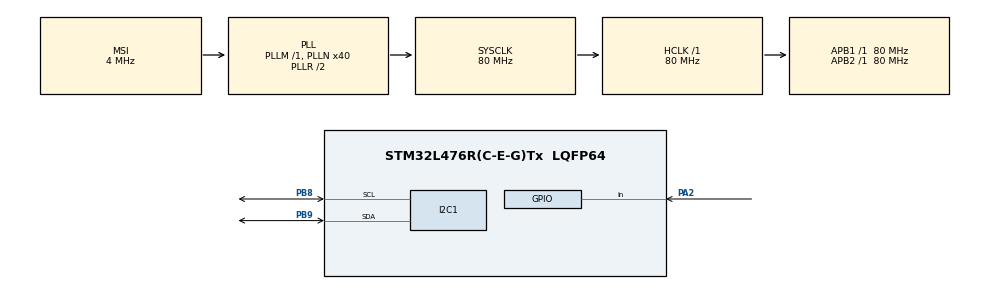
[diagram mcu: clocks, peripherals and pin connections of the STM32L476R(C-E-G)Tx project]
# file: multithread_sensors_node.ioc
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FREERTOS.Mutexes01=I2C1_bus,Dynamic,NULL,Available
FREERTOS.Queues01=i2c_gyro,8,DebugMsg_t,0,Dynamic,NULL,NULL
FREERTOS.Tasks01=health_debug_ta,24,128,check_cpu_health,Default,NULL,Dynamic,NULL,NULL;i2c_read_write_,24,256,i2c_read_write,Default,NULL,Dynamic,NULL,NULL;DHT11_TH_Sensor,25,256,dht11_rw,Default,NULL,Dynamic,NULL,NULL
FREERTOS.configTOTAL_HEAP_SIZE=5000
I2C1.Timing=0x10D19CE4
Mcu.Family=STM32L4
Mcu.Name=STM32L476R(C-E-G)Tx
Mcu.Package=LQFP64
NVIC.PriorityGroup=NVIC_PRIORITYGROUP_4
NVIC.TIM6_DAC_IRQn=true\:15\:0\:false\:false\:true\:false\:false\:true\:true
NVIC.TimeBase=TIM6_DAC_IRQn
NVIC.TimeBaseIP=TIM6
PA13\ (JTMS-SWDIO).Mode=Serial_Wire
PA13\ (JTMS-SWDIO).Signal=SYS_JTMS-SWDIO
PA14\ (JTCK-SWCLK).Mode=Serial_Wire
PA14\ (JTCK-SWCLK).Signal=SYS_JTCK-SWCLK
PA2.Signal=GPIO_Input
PB8.Mode=I2C
PB8.Signal=I2C1_SCL
PB9.Mode=I2C
PB9.Signal=I2C1_SDA
ProjectManager.HeapSize=0x200
ProjectManager.StackSize=0x400
ProjectManager.TargetToolchain=STM32CubeIDE
RCC.AHBFreq_Value=80000000
RCC.APB1Freq_Value=80000000
RCC.APB1TimFreq_Value=80000000
RCC.APB2Freq_Value=80000000
RCC.APB2TimFreq_Value=80000000
RCC.CortexFreq_Value=80000000
RCC.HCLKFreq_Value=80000000
RCC.HSE_VALUE=8000000
RCC.HSI_VALUE=16000000
RCC.LSE_VALUE=32768
RCC.MSI_VALUE=4000000
RCC.PLLN=40
RCC.SYSCLKFreq_VALUE=80000000
RCC.SYSCLKSource=RCC_SYSCLKSOURCE_PLLCLK
RCC.VCOOutputFreq_Value=160000000
TIM2.AutoReloadPreload=TIM_AUTORELOAD_PRELOAD_ENABLE
TIM2.Period=65535-1
TIM2.Prescaler=80-1
TIM2.TIM_MasterOutputTrigger=TIM_TRGO_RESET
TIM2.TIM_MasterSlaveMode=TIM_MASTERSLAVEMODE_DISABLE
VP_FREERTOS_VS_CMSIS_V2.Mode=CMSIS_V2
VP_SYS_VS_tim6.Mode=TIM6
VP_TIM2_VS_ClockSourceINT.Mode=Internal
board=custom

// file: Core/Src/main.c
/* USER CODE BEGIN Header */
/**
  ******************************************************************************
  * @file           : main.c
  * @brief          : Main program body
  ******************************************************************************
  * @attention
  *
  * Copyright (c) 2026 STMicroelectronics.
  * All rights reserved.
  *
  * This software is licensed under terms that can be found in the LICENSE file
  * in the root directory of this software component.
  * If no LICENSE file comes with this software, it is provided AS-IS.
  *
  ******************************************************************************
  */
/* USER CODE END Header */
#include "main.h"
#include "cmsis_os.h"

I2C_HandleTypeDef hi2c1;

TIM_HandleTypeDef htim2;

/* Definitions for health_debug_ta */
osThreadId_t health_debug_taHandle;
const osThreadAttr_t health_debug_ta_attributes = {
  .name = "health_debug_ta",
  .stack_size = 128 * 4,
  .priority = (osPriority_t) osPriorityNormal,
};
/* Definitions for i2c_read_write_ */
osThreadId_t i2c_read_write_Handle;
const osThreadAttr_t i2c_read_write__attributes = {
  .name = "i2c_read_write_",
  .stack_size = 256 * 4,
  .priority = (osPriority_t) osPriorityNormal,
};
/* Definitions for DHT11_TH_Sensor */
osThreadId_t DHT11_TH_SensorHandle;
const osThreadAttr_t DHT11_TH_Sensor_attributes = {
  .name = "DHT11_TH_Sensor",
  .stack_size = 256 * 4,
  .priority = (osPriority_t) osPriorityNormal1,
};
/* Definitions for i2c_gyro */
osMessageQueueId_t i2c_gyroHandle;
const osMessageQueueAttr_t i2c_gyro_attributes = {
  .name = "i2c_gyro"
};
/* Definitions for I2C1_bus */
osMutexId_t I2C1_busHandle;
const osMutexAttr_t I2C1_bus_attributes = {
  .name = "I2C1_bus"
};

void SystemClock_Config(void);
static void MX_GPIO_Init(void);
static void MX_I2C1_Init(void);
static void MX_TIM2_Init(void);
void check_cpu_health(void *argument);
void i2c_read_write(void *argument);
void dht11_rw(void *argument);

/* USER CODE BEGIN PFP */
dht11_t dht;
/* USER CODE END PFP */

int main(void)
{

  /* USER CODE BEGIN 1 */
	char buff[15];
  /* USER CODE END 1 */

  /* MCU Configuration--------------------------------------------------------*/

  /* Reset of all peripherals, Initializes the Flash interface and the Systick. */
  HAL_Init();

  /* Configure the system clock */
  SystemClock_Config();

  /* Initialize all configured peripherals */
  MX_GPIO_Init();
  MX_I2C1_Init();
  MX_TIM2_Init();
  /* USER CODE BEGIN 2 */

  init_dht11(&dht, &htim2, GPIOA, GPIO_PIN_8);

  HAL_Delay(100);
  /* USER CODE END 2 */

  /* Init scheduler */
  osKernelInitialize();
  /* Create the mutex(es) */
  /* creation of I2C1_bus */
  I2C1_busHandle = osMutexNew(&I2C1_bus_attributes);

  /* Create the queue(s) */
  /* creation of i2c_gyro */
  i2c_gyroHandle = osMessageQueueNew (8, sizeof(DebugMsg_t), &i2c_gyro_attributes);

  /* USER CODE BEGIN RTOS_QUEUES */
  if(i2c_gyroHandle == NULL)
  {
	  sprintf(buff, "Queue Error");
	  send_string(buff);
  }
  /* add queues, ... */
  /* USER CODE END RTOS_QUEUES */

  /* Create the thread(s) */
  /* creation of health_debug_ta */
  health_debug_taHandle = osThreadNew(check_cpu_health, NULL, &health_debug_ta_attributes);

  /* creation of i2c_read_write_ */
//  i2c_read_write_Handle = osThreadNew(i2c_read_write, NULL, &i2c_read_write__attributes);

  /* creation of DHT11_TH_Sensor */
  DHT11_TH_SensorHandle = osThreadNew(dht11_rw, NULL, &DHT11_TH_Sensor_attributes);

  /* Start scheduler */
  osKernelStart();

  /* We should never get here as control is now taken by the scheduler */

  /* Infinite loop */
  while (1)
  {

  }
}

void SystemClock_Config(void)
{
  RCC_OscInitTypeDef RCC_OscInitStruct = {0};
  RCC_ClkInitTypeDef RCC_ClkInitStruct = {0};

  /** Configure the main internal regulator output voltage
  */
  if (HAL_PWREx_ControlVoltageScaling(PWR_REGULATOR_VOLTAGE_SCALE1) != HAL_OK)
  {
    Error_Handler();
  }

  /** Initializes the RCC Oscillators according to the specified parameters
  * in the RCC_OscInitTypeDef structure.
  */
  RCC_OscInitStruct.OscillatorType = RCC_OSCILLATORTYPE_MSI;
  RCC_OscInitStruct.MSIState = RCC_MSI_ON;
  RCC_OscInitStruct.MSICalibrationValue = 0;
  RCC_OscInitStruct.MSIClockRange = RCC_MSIRANGE_6;
  RCC_OscInitStruct.PLL.PLLState = RCC_PLL_ON;
  RCC_OscInitStruct.PLL.PLLSource = RCC_PLLSOURCE_MSI;
  RCC_OscInitStruct.PLL.PLLM = 1;
  RCC_OscInitStruct.PLL.PLLN = 40;
  RCC_OscInitStruct.PLL.PLLP = RCC_PLLP_DIV7;
  RCC_OscInitStruct.PLL.PLLQ = RCC_PLLQ_DIV2;
  RCC_OscInitStruct.PLL.PLLR = RCC_PLLR_DIV2;
  if (HAL_RCC_OscConfig(&RCC_OscInitStruct) != HAL_OK)
  {
    Error_Handler();
  }

  /** Initializes the CPU, AHB and APB buses clocks
  */
  RCC_ClkInitStruct.ClockType = RCC_CLOCKTYPE_HCLK|RCC_CLOCKTYPE_SYSCLK
                              |RCC_CLOCKTYPE_PCLK1|RCC_CLOCKTYPE_PCLK2;
  RCC_ClkInitStruct.SYSCLKSource = RCC_SYSCLKSOURCE_PLLCLK;
  RCC_ClkInitStruct.AHBCLKDivider = RCC_SYSCLK_DIV1;
  RCC_ClkInitStruct.APB1CLKDivider = RCC_HCLK_DIV1;
  RCC_ClkInitStruct.APB2CLKDivider = RCC_HCLK_DIV1;

  if (HAL_RCC_ClockConfig(&RCC_ClkInitStruct, FLASH_LATENCY_4) != HAL_OK)
  {
    Error_Handler();
  }
}

static void MX_I2C1_Init(void)
{

  hi2c1.Instance = I2C1;
  hi2c1.Init.Timing = 0x10D19CE4;
  hi2c1.Init.OwnAddress1 = 0;
  hi2c1.Init.AddressingMode = I2C_ADDRESSINGMODE_7BIT;
  hi2c1.Init.DualAddressMode = I2C_DUALADDRESS_DISABLE;
  hi2c1.Init.OwnAddress2 = 0;
  hi2c1.Init.OwnAddress2Masks = I2C_OA2_NOMASK;
  hi2c1.Init.GeneralCallMode = I2C_GENERALCALL_DISABLE;
  hi2c1.Init.NoStretchMode = I2C_NOSTRETCH_DISABLE;
  if (HAL_I2C_Init(&hi2c1) != HAL_OK)
  {
    Error_Handler();
  }

  /** Configure Analogue filter
  */
  if (HAL_I2CEx_ConfigAnalogFilter(&hi2c1, I2C_ANALOGFILTER_ENABLE) != HAL_OK)
  {
    Error_Handler();
  }

  /** Configure Digital filter
  */
  if (HAL_I2CEx_ConfigDigitalFilter(&hi2c1, 0) != HAL_OK)
  {
    Error_Handler();
  }

}

static void MX_TIM2_Init(void)
{

  TIM_ClockConfigTypeDef sClockSourceConfig = {0};
  TIM_MasterConfigTypeDef sMasterConfig = {0};

  htim2.Instance = TIM2;
  htim2.Init.Prescaler = 80-1;
  htim2.Init.CounterMode = TIM_COUNTERMODE_UP;
  htim2.Init.Period = 65535-1;
  htim2.Init.ClockDivision = TIM_CLOCKDIVISION_DIV1;
  htim2.Init.AutoReloadPreload = TIM_AUTORELOAD_PRELOAD_ENABLE;
  if (HAL_TIM_Base_Init(&htim2) != HAL_OK)
  {
    Error_Handler();
  }
  sClockSourceConfig.ClockSource = TIM_CLOCKSOURCE_INTERNAL;
  if (HAL_TIM_ConfigClockSource(&htim2, &sClockSourceConfig) != HAL_OK)
  {
    Error_Handler();
  }
  sMasterConfig.MasterOutputTrigger = TIM_TRGO_RESET;
  sMasterConfig.MasterSlaveMode = TIM_MASTERSLAVEMODE_DISABLE;
  if (HAL_TIMEx_MasterConfigSynchronization(&htim2, &sMasterConfig) != HAL_OK)
  {
    Error_Handler();
  }

}

static void MX_GPIO_Init(void)
{
  GPIO_InitTypeDef GPIO_InitStruct = {0};

  /* GPIO Ports Clock Enable */
  __HAL_RCC_GPIOA_CLK_ENABLE();
  __HAL_RCC_GPIOB_CLK_ENABLE();

  /*Configure GPIO pin : PA2 */
  GPIO_InitStruct.Pin = GPIO_PIN_2;
  GPIO_InitStruct.Mode = GPIO_MODE_INPUT;
  GPIO_InitStruct.Pull = GPIO_NOPULL;
  HAL_GPIO_Init(GPIOA, &GPIO_InitStruct);

}

/* USER CODE BEGIN 4 */
void send_string(const char *message)
{
	while(*message)
	{
		ITM_SendChar(*message);
		message++;
	}
	ITM_SendChar('\n');
}
/* USER CODE END 4 */

void check_cpu_health(void *argument)
{
  /* USER CODE BEGIN 5 */
  DebugMsg_t rxMsg; // Allocate actual space on the stack

  for(;;)
  {
    // Pass the address of the struct container
    if(osMessageQueueGet(i2c_gyroHandle, &rxMsg, NULL, 2000) == osOK)
    {
        send_string(rxMsg.text); // Pass the inner string to your ITM function
    }
    else
    {
    	send_string("CPU Health OK..");
    }
  }
  /* USER CODE END 5 */
}

void i2c_read_write(void *argument)
{
  /* USER CODE BEGIN i2c_read_write */
	DebugMsg_t txMsg;
	uint8_t dev_id = 0;
	uint16_t x_axis, y_axis, z_axis;
	float x_axis_g, y_axis_g,z_axis_g, x_angle, y_angle;
	osStatus_t q_status;

#if 1
	// Finding a Device on I2C1 Bus
	for(int i = 0; i < 128; i++)
	{
		if(HAL_I2C_IsDeviceReady(&hi2c1,(uint16_t)(i<<1), 2, 5) == 0)
		{
			// Safe print directly into the struct's text array
			snprintf(txMsg.text, sizeof(txMsg.text), "Device Found 0x%02xh", i);

			// The queue copies all 32 bytes of txMsg safely by value
			q_status = osMessageQueuePut(i2c_gyroHandle, &txMsg, 0, 100);
			if(q_status == osOK)
				break;
		}
	}
#endif

	//Getting Device ID
	dev_id = i2c_read_devid(ADXL345_ADDR);
	if(dev_id != FAILURE)
	{
		snprintf(txMsg.text, sizeof(txMsg.text), "Device ID: 0x%02xh", dev_id);
		osMessageQueuePut(i2c_gyroHandle, &txMsg, 0, 100);
	}

	i2c_write_register(ADXL345_ADDR, POWER_CTL, 0x00);
	i2c_write_register(ADXL345_ADDR, POWER_CTL, 0x08);
	i2c_write_register(ADXL345_ADDR, DATA_FORMAT, 0x01);

	osDelay(100);

  /* Infinite loop */
  for(;;)
  {

	  x_axis = i2c_read_x_axis();
	  y_axis = i2c_read_y_axis();
	  z_axis = i2c_read_z_axis();

	  x_axis_g = x_axis * .0078;
	  y_axis_g = y_axis * .0078;
	  z_axis_g = z_axis * .0078;

	  snprintf(txMsg.text, sizeof(txMsg.text), "%.2f %.2f %.2f\n\r", x_axis_g, y_axis_g, z_axis_g);
	  osMessageQueuePut(i2c_gyroHandle, &txMsg, 0, 100);

	  x_angle = atan2(x_axis_g, z_axis_g);
	  x_angle = x_angle * 180.0 / PI;

	  y_angle = atan2(y_axis, z_axis);
	  y_angle = y_angle * 180.0 / PI;

	  snprintf(txMsg.text, sizeof(txMsg.text), "x_angle%.2f, y_angle%.2f", x_angle, y_angle);
	  osMessageQueuePut(i2c_gyroHandle, &txMsg, 0, 100);

	osDelay(500);
  }
  /* USER CODE END i2c_read_write */
}

void dht11_rw(void *argument)
{
  /* USER CODE BEGIN dht11_rw */
	DebugMsg_t txMsg;
  /* Infinite loop */
  for(;;)
  {
	  if(readDHT11(&dht) == 0)
	  {
		  snprintf(txMsg.text, sizeof(txMsg.text), "Error in %s...", __func__);
		  osMessageQueuePut(i2c_gyroHandle, &txMsg, 0, 100);
	  }
	  else
	  {
		  snprintf(txMsg.text, sizeof(txMsg.text), "T: %d, H: %d", dht.temperature, dht.humidty);
		  osMessageQueuePut(i2c_gyroHandle, &txMsg, 0, 100);
	  }

    osDelay(500);
  }
  /* USER CODE END dht11_rw */
}

void HAL_TIM_PeriodElapsedCallback(TIM_HandleTypeDef *htim)
{
  if (htim->Instance == TIM6)
  {
    HAL_IncTick();
  }
}

void Error_Handler(void)
{
  __disable_irq();
  while (1)
  {
  }
}
